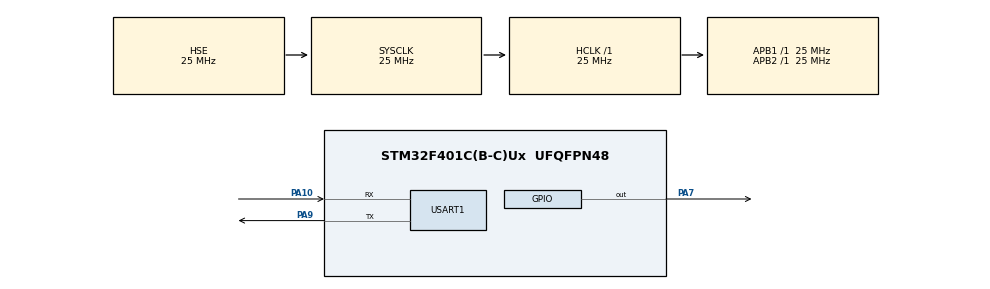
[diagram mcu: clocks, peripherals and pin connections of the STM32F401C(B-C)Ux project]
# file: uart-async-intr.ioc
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Mcu.Family=STM32F4
Mcu.Name=STM32F401C(B-C)Ux
Mcu.Package=UFQFPN48
NVIC.PriorityGroup=NVIC_PRIORITYGROUP_4
NVIC.USART1_IRQn=true\:0\:0\:false\:false\:true\:true\:true\:true
PA10.Mode=Asynchronous
PA10.Signal=USART1_RX
PA13.Mode=Serial_Wire
PA13.Signal=SYS_JTMS-SWDIO
PA14.Mode=Serial_Wire
PA14.Signal=SYS_JTCK-SWCLK
PA7.PinState=GPIO_PIN_SET
PA7.Signal=GPIO_Output
PA9.Mode=Asynchronous
PA9.Signal=USART1_TX
PH0\ -\ OSC_IN.Mode=HSE-External-Oscillator
PH0\ -\ OSC_IN.Signal=RCC_OSC_IN
PH1\ -\ OSC_OUT.Mode=HSE-External-Oscillator
PH1\ -\ OSC_OUT.Signal=RCC_OSC_OUT
ProjectManager.HeapSize=0x200
ProjectManager.StackSize=0x400
ProjectManager.TargetToolchain=STM32CubeIDE
RCC.48MHZClocksFreq_Value=75000000
RCC.AHBFreq_Value=25000000
RCC.APB1Freq_Value=25000000
RCC.APB1TimFreq_Value=25000000
RCC.APB2Freq_Value=25000000
RCC.APB2TimFreq_Value=25000000
RCC.CortexFreq_Value=25000000
RCC.HCLKFreq_Value=25000000
RCC.HSE_VALUE=25000000
RCC.HSI_VALUE=16000000
RCC.LSE_VALUE=32768
RCC.PLLSourceVirtual=RCC_PLLSOURCE_HSE
RCC.SYSCLKFreq_VALUE=25000000
RCC.SYSCLKSource=RCC_SYSCLKSOURCE_HSE
RCC.VCOOutputFreq_Value=300000000
USART1.VirtualMode=VM_ASYNC
board=custom

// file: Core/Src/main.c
/* USER CODE BEGIN Header */
/**
  ******************************************************************************
  * @file           : main.c
  * @brief          : Main program body
  ******************************************************************************
  * @attention
  *
  * Copyright (c) 2025 STMicroelectronics.
  * All rights reserved.
  *
  * This software is licensed under terms that can be found in the LICENSE file
  * in the root directory of this software component.
  * If no LICENSE file comes with this software, it is provided AS-IS.
  *
  ******************************************************************************
  */
/* USER CODE END Header */
#include "main.h"

/* USER CODE BEGIN Includes */
#include "stm32f4xx_hal.h"
#include <stdio.h>
#include <string.h>
#include <stdint.h>
#include <stdbool.h>

/* USER CODE END Includes */

UART_HandleTypeDef huart1;

/* USER CODE BEGIN PV */
#define RPI_RX_BUFFER_SIZE 33
uint8_t rpi_rx_buffer[RPI_RX_BUFFER_SIZE];
bool RPI_BUFF_RECEIVED = false;
uint16_t RxDataLen = 0;
uint8_t rx_data = 0;
/* USER CODE END PV */

void SystemClock_Config(void);
static void MX_GPIO_Init(void);
static void MX_USART1_UART_Init(void);

int main(void)
{

  /* MCU Configuration--------------------------------------------------------*/

  /* Reset of all peripherals, Initializes the Flash interface and the Systick. */
  HAL_Init();

  /* Configure the system clock */
  SystemClock_Config();

  /* Initialize all configured peripherals */
  MX_GPIO_Init();
  MX_USART1_UART_Init();
  /* USER CODE BEGIN 2 */
//  HAL_UARTEx_ReceiveToIdle_IT(&huart1, rx_data, 1);
  HAL_UARTEx_ReceiveToIdle_IT(&huart1, rpi_rx_buffer, RPI_RX_BUFFER_SIZE);

  /* USER CODE END 2 */

  /* Infinite loop */
  /* USER CODE BEGIN WHILE */
  while (1)
  {
	  if(RPI_BUFF_RECEIVED){
		  HAL_GPIO_WritePin(GPIOA, GPIO_PIN_7, GPIO_PIN_RESET);
		  RPI_BUFF_RECEIVED =! RPI_BUFF_RECEIVED;
		  HAL_Delay(1000);
		  HAL_GPIO_WritePin(GPIOA, GPIO_PIN_7, GPIO_PIN_SET);
		  memset(rpi_rx_buffer, 0x00, RPI_RX_BUFFER_SIZE); // Clear invalid buffer
			/* Restart UART receive interrupt */
			HAL_UARTEx_ReceiveToIdle_IT(&huart1, rpi_rx_buffer, RPI_RX_BUFFER_SIZE);
	  }
    /* USER CODE END WHILE */

    /* USER CODE BEGIN 3 */
	  HAL_Delay(50);
  }
  /* USER CODE END 3 */
}

void SystemClock_Config(void)
{
  RCC_OscInitTypeDef RCC_OscInitStruct = {0};
  RCC_ClkInitTypeDef RCC_ClkInitStruct = {0};

  /** Configure the main internal regulator output voltage
  */
  __HAL_RCC_PWR_CLK_ENABLE();
  __HAL_PWR_VOLTAGESCALING_CONFIG(PWR_REGULATOR_VOLTAGE_SCALE2);

  /** Initializes the RCC Oscillators according to the specified parameters
  * in the RCC_OscInitTypeDef structure.
  */
  RCC_OscInitStruct.OscillatorType = RCC_OSCILLATORTYPE_HSE;
  RCC_OscInitStruct.HSEState = RCC_HSE_ON;
  RCC_OscInitStruct.PLL.PLLState = RCC_PLL_NONE;
  if (HAL_RCC_OscConfig(&RCC_OscInitStruct) != HAL_OK)
  {
    Error_Handler();
  }

  /** Initializes the CPU, AHB and APB buses clocks
  */
  RCC_ClkInitStruct.ClockType = RCC_CLOCKTYPE_HCLK|RCC_CLOCKTYPE_SYSCLK
                              |RCC_CLOCKTYPE_PCLK1|RCC_CLOCKTYPE_PCLK2;
  RCC_ClkInitStruct.SYSCLKSource = RCC_SYSCLKSOURCE_HSE;
  RCC_ClkInitStruct.AHBCLKDivider = RCC_SYSCLK_DIV1;
  RCC_ClkInitStruct.APB1CLKDivider = RCC_HCLK_DIV1;
  RCC_ClkInitStruct.APB2CLKDivider = RCC_HCLK_DIV1;

  if (HAL_RCC_ClockConfig(&RCC_ClkInitStruct, FLASH_LATENCY_0) != HAL_OK)
  {
    Error_Handler();
  }
}

static void MX_USART1_UART_Init(void)
{

  huart1.Instance = USART1;
  huart1.Init.BaudRate = 115200;
  huart1.Init.WordLength = UART_WORDLENGTH_8B;
  huart1.Init.StopBits = UART_STOPBITS_1;
  huart1.Init.Parity = UART_PARITY_NONE;
  huart1.Init.Mode = UART_MODE_TX_RX;
  huart1.Init.HwFlowCtl = UART_HWCONTROL_NONE;
  huart1.Init.OverSampling = UART_OVERSAMPLING_16;
  if (HAL_UART_Init(&huart1) != HAL_OK)
  {
    Error_Handler();
  }

}

static void MX_GPIO_Init(void)
{
  GPIO_InitTypeDef GPIO_InitStruct = {0};

  /* GPIO Ports Clock Enable */
  __HAL_RCC_GPIOH_CLK_ENABLE();
  __HAL_RCC_GPIOA_CLK_ENABLE();

  /*Configure GPIO pin Output Level */
  HAL_GPIO_WritePin(GPIOA, GPIO_PIN_7, GPIO_PIN_SET);

  /*Configure GPIO pin : PA7 */
  GPIO_InitStruct.Pin = GPIO_PIN_7;
  GPIO_InitStruct.Mode = GPIO_MODE_OUTPUT_PP;
  GPIO_InitStruct.Pull = GPIO_NOPULL;
  GPIO_InitStruct.Speed = GPIO_SPEED_FREQ_LOW;
  HAL_GPIO_Init(GPIOA, &GPIO_InitStruct);

}
uint8_t counter = 0;
/* USER CODE BEGIN 4 */
/* UART Receive Complete Callback */
void HAL_UARTEx_RxEventCallback(UART_HandleTypeDef *huart, uint16_t Size) {
	if (huart->Instance == USART1) // Check if the interrupt is from USART1
	{
		/* Validate packet length and format */
//		if (validatePacket(rpi_rx_buffer, RPI_RX_BUFFER_SIZE)) {
//			memcpy(rpi_buff, rpi_rx_buffer, RPI_BUFF_SIZE);
			// Mark as received only if valid
//		} else {
////			memset(rpi_rx_buffer, 0x00, RPI_RX_BUFFER_SIZE); // Clear invalid buffer
//		}
		RxDataLen = Size;
		if(RxDataLen == 33){
			RPI_BUFF_RECEIVED = true;
			HAL_UART_Transmit(&huart1, rpi_rx_buffer, RxDataLen, 100);
		}

//		HAL_UARTEx_ReceiveToIdle_IT(&huart1, rx_data, 1);
	}
}

void HAL_UART_ErrorCallback(UART_HandleTypeDef *huart) {
	if (huart->Instance == USART1) {
		/* Clear all relevant UART error flags */
		__HAL_UART_CLEAR_FLAG(huart,
				UART_FLAG_ORE | UART_FLAG_NE | UART_FLAG_FE | UART_FLAG_PE);

		/* Restart UART reception */
		HAL_UART_Receive_IT(&huart1, rpi_rx_buffer, RPI_RX_BUFFER_SIZE);
	}
}

/* USER CODE END 4 */

void Error_Handler(void)
{
  __disable_irq();
  while (1)
  {
  }
}
